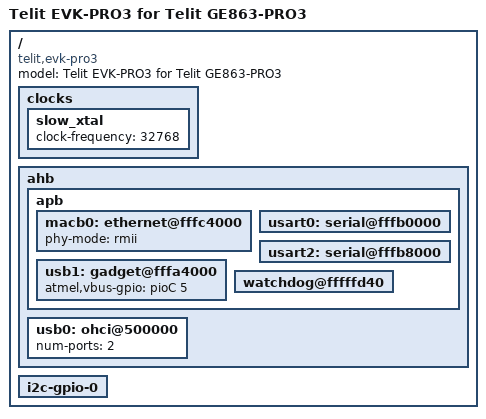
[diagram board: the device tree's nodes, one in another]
// SPDX-License-Identifier: GPL-2.0-or-later
/*
 * evk-pro3.dts - Device Tree file for Telit EVK-PRO3 with Telit GE863-PRO3
 *
 * Copyright (C) 2012 Telit,
 *               2012 Fabio Porcedda <fabio.porcedda@gmail.com>
 */

/dts-v1/;

#include "ge863-pro3.dtsi"

/ {
	model = "Telit EVK-PRO3 for Telit GE863-PRO3";
	compatible = "telit,evk-pro3", "atmel,at91sam9260", "atmel,at91sam9";

	clocks {
		slow_xtal {
			clock-frequency = <32768>;
		};
	};

	ahb {
		apb {
			macb0: ethernet@fffc4000 {
				phy-mode = "rmii";
				status = "okay";
			};

			usart0: serial@fffb0000 {
				status = "okay";
			};

			usart2: serial@fffb8000 {
				status = "okay";
			};

			usb1: gadget@fffa4000 {
				atmel,vbus-gpio = <&pioC 5 GPIO_ACTIVE_HIGH>;
				status = "okay";
			};

			watchdog@fffffd40 {
				status = "okay";
			};
		};

		usb0: ohci@500000 {
			num-ports = <2>;
			status = "okay";
		};
	};

	i2c-gpio-0 {
		status = "okay";
	};

};
